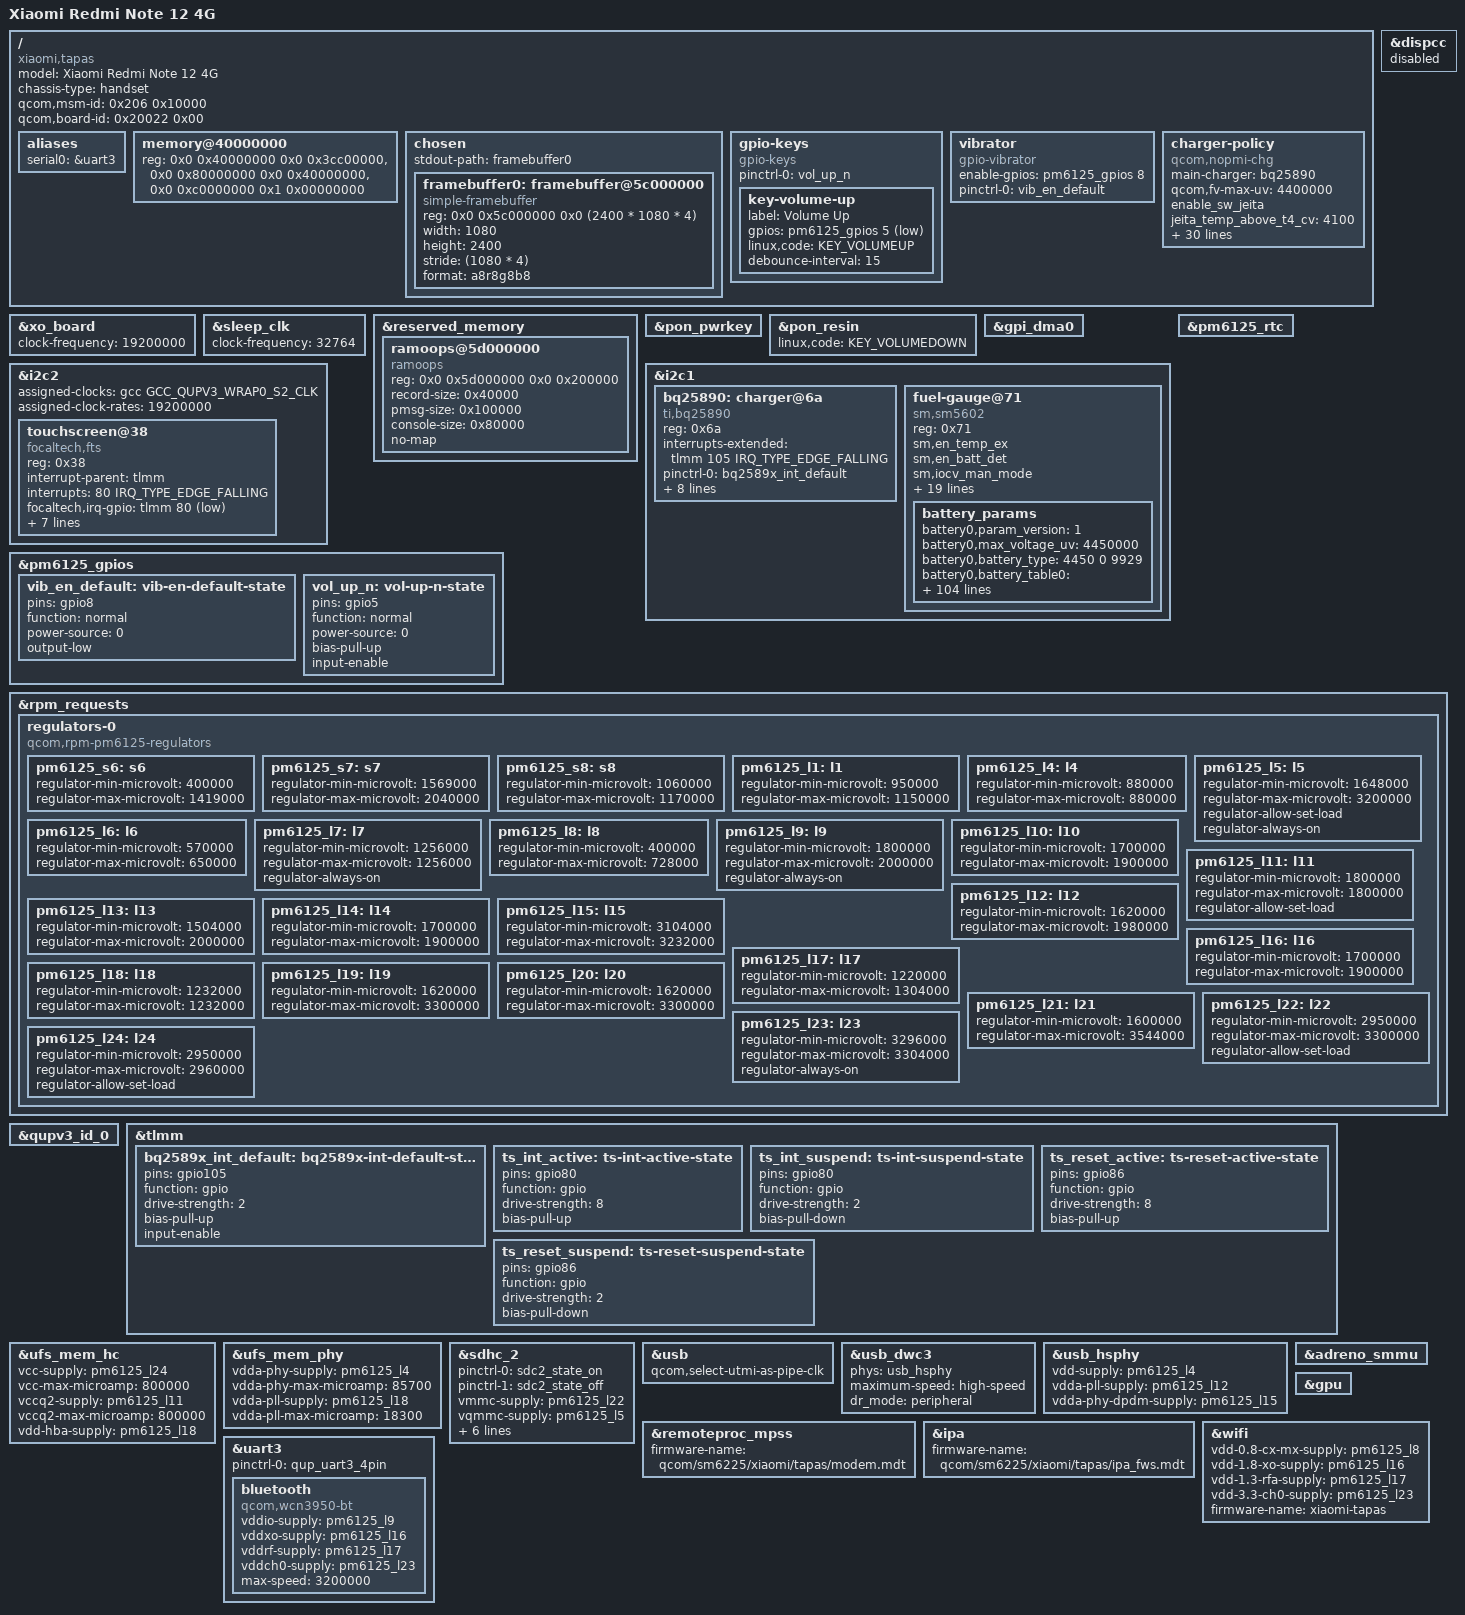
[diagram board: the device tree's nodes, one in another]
// SPDX-License-Identifier: GPL-2.0-only
/*
 * Xiaomi Redmi Note 12 4G (tapas), SM6225 "Khaje".
 *
 * Built on the sm6225.dtsi of the sm6225-mainline kernel
 * (https://gitlab.postmarketos.org/sm6225-mainline), laid out like its
 * Redmi Note 11 (spes) board file, which shares most of the tapas board:
 * same PMIC, charger, Type-C controller and I2C buses.
 *
 * Display is the framebuffer the bootloader leaves on (no panel driver).
 * The bootloader does not see this DTB (shim/start.S passes it), so it does
 * not fill in the memory node either: the layout below is the one ABL
 * reports on the 6 GB model.
 */
/dts-v1/;
#include "sm6225.dtsi"
#include "pm6125.dtsi"
#include <dt-bindings/gpio/gpio.h>
#include <dt-bindings/interrupt-controller/irq.h>
#include <dt-bindings/input/linux-event-codes.h>

/delete-node/ &{/memory@80000000};

/ {
	model = "Xiaomi Redmi Note 12 4G";
	compatible = "xiaomi,tapas", "qcom,sm6225";
	chassis-type = "handset";

	qcom,msm-id = <0x206 0x10000>;
	qcom,board-id = <0x20022 0x00>;

	aliases {
		serial0 = &uart3;
	};

	/* ABL's "RAM Partitions" on the 6 GB tapas */
	memory@40000000 {
		device_type = "memory";
		reg = <0x0 0x40000000 0x0 0x3cc00000>,
		      <0x0 0x80000000 0x0 0x40000000>,
		      <0x0 0xc0000000 0x1 0x00000000>;
	};

	chosen {
		#address-cells = <2>;
		#size-cells = <2>;
		ranges;
		stdout-path = "framebuffer0";

		/* 1080x2400, 32 bpp: the splash buffer the bootloader scans out */
		framebuffer0: framebuffer@5c000000 {
			compatible = "simple-framebuffer";
			reg = <0x0 0x5c000000 0x0 (2400 * 1080 * 4)>;
			width = <1080>;
			height = <2400>;
			stride = <(1080 * 4)>;
			format = "a8r8g8b8";
		};
	};

	gpio-keys {
		compatible = "gpio-keys";
		pinctrl-names = "default";
		pinctrl-0 = <&vol_up_n>;

		key-volume-up {
			label = "Volume Up";
			gpios = <&pm6125_gpios 5 GPIO_ACTIVE_LOW>;
			linux,code = <KEY_VOLUMEUP>;
			debounce-interval = <15>;
		};
	};

	/* Stock vibrator_gpio: the motor runs while PM6125 GPIO8 is high */
	vibrator {
		compatible = "gpio-vibrator";
		enable-gpios = <&pm6125_gpios 8 GPIO_ACTIVE_HIGH>;
		pinctrl-0 = <&vib_en_default>;
		pinctrl-names = "default";
	};

	/*
	 * Xiaomi "No-PMI" charger policy, as on spes: turns the SM5602 fuel
	 * gauge ("bms") and the bq2589x buck into the "battery" and "usb"
	 * supplies that UPower reads. Values from the stock qcom,nopmi-chg
	 * node. No pd-source: the rt1711h Type-C port is left out for now.
	 */
	charger-policy {
		compatible = "qcom,nopmi-chg";
		main-charger = <&bq25890>;
		qcom,fv-max-uv = <4400000>;

		enable_sw_jeita;
		jeita_temp_above_t4_cv = <4100>;
		jeita_temp_t3_to_t4_cv = <4100>;
		jeita_temp_t2_to_t3_cv = <4450>;
		jeita_temp_t1p5_to_t2_cv = <4450>;
		jeita_temp_t1_to_t1p5_cv = <4450>;
		jeita_temp_t0_to_t1_cv = <4450>;
		jeita_temp_tn1_to_t0_cv = <4450>;
		jeita_temp_below_t0_cv = <4450>;
		temp_t4_thres = <60>;
		temp_t4_thres_minus_x_degree = <58>;
		temp_t3_thres = <48>;
		temp_t3_thres_minus_x_degree = <46>;
		temp_t2_thres = <15>;
		temp_t2_thres_plus_x_degree = <17>;
		temp_t1p5_thres = <10>;
		temp_t1p5_thres_plus_x_degree = <11>;
		temp_t1_thres = <5>;
		temp_t1_thres_plus_x_degree = <6>;
		temp_t0_thres = <0>;
		temp_t0_thres_plus_x_degree = <1>;
		temp_tn1_thres = <(-10)>;
		temp_tn1_thres_plus_x_degree = <(-9)>;
		temp_neg_10_thres = <(-10)>;
		temp_t3_to_t4_fcc = <2350>;
		temp_t2_to_t3_fcc = <5950>;
		temp_t1p5_to_t2_fcc = <3900>;
		temp_t1_to_t1p5_fcc = <2400>;
		temp_t0_to_t1_fcc = <950>;
		temp_tn1_to_t0_fcc = <490>;
		nopmi,thermal-mitigation = <5950000 5400000 5000000 4500000 4000000
					    3700000 3500000 3000000 2800000 2500000
					    2000000 1500000 1000000 800000 500000
					    350000 800000 800000>;
	};
};

/*
 * The SoC dtsi leaves the board clock rates to the board. Without them
 * xo_board never registers, bi_tcxo stays an orphan at 0 Hz, and the QUP
 * DFS tables read back as all zeros (geni_i2c: "Unsupported SE source
 * clock"), so i2c2 and the touchscreen never probe.
 */
&xo_board {
	clock-frequency = <19200000>;
};

&sleep_clk {
	clock-frequency = <32764>;
};

&reserved_memory {
	/*
	 * Same place and layout as the stock kernel, so the log of a boot
	 * that died can be read from Android or recovery afterwards.
	 */
	ramoops@5d000000 {
		compatible = "ramoops";
		reg = <0x0 0x5d000000 0x0 0x200000>;
		record-size = <0x40000>;
		pmsg-size = <0x100000>;
		console-size = <0x80000>;
		no-map;
	};
};

/*
 * Leave the display clocks as the bootloader set them: dispcc reprograms
 * its PLL when it probes, which broke the splash scanout under the
 * framebuffer (grey screen, blue stripes). The MDSS is disabled anyway.
 */
&dispcc {
	status = "disabled";
};

&pon_pwrkey {
	status = "okay";
};

&pon_resin {
	linux,code = <KEY_VOLUMEDOWN>;
	status = "okay";
};

&gpi_dma0 {
	status = "okay";
};

/*
 * Charger and fuel gauge, at the stock addresses. Left out for now: the
 * rt1711h Type-C port (0x4e, it would renegotiate the USB link the
 * bring-up shell runs on), the sc8551/ln8000 divider pumps and the audio
 * amplifiers.
 */
&i2c1 {
	status = "okay";

	/* Stock "ti,bq2589x-1"; the sm6225-mainline driver knows its id */
	bq25890: charger@6a {
		compatible = "ti,bq25890";
		reg = <0x6a>;
		interrupts-extended = <&tlmm 105 IRQ_TYPE_EDGE_FALLING>;
		pinctrl-0 = <&bq2589x_int_default>;
		pinctrl-names = "default";

		/* Stock charge-voltage, charge-current and term-current */
		ti,battery-regulation-voltage = <4450000>;
		ti,charge-current = <2000000>;
		ti,termination-current = <256000>;
		ti,precharge-current = <128000>;
		ti,minimum-sys-voltage = <3500000>;
		ti,boost-voltage = <5000000>;
		ti,boost-max-current = <1500000>;
		/*
		 * No ti,enable-auto-dpdm: stock routes D+/D- to the charger
		 * through a switch (gpio66) for that, and here they belong to
		 * the USB gadget.
		 */
		/*
		 * Keep the bootloader's register state: a chip reset turns
		 * OTG_CONFIG back on (its default), and the phone would start
		 * putting 5 V on the cable to the fastboot host.
		 */
		linux,skip-reset;
	};

	fuel-gauge@71 {
		compatible = "sm,sm5602";
		reg = <0x71>;

		/* From the stock node; profile 0 is used without batt_verify */
		sm,en_temp_ex;
		sm,en_batt_det;
		sm,iocv_man_mode;
		sm,misc = <2048>;
		sm,aging_ctrl = <289>;
		sm,cycle_cfg = <28672>;
		sm,rsns = <0>;
		sm,rtrace = <2000>;
		sm,fg_irq_set = <2047>;
		sm,low_soc1 = <1>;
		sm,low_soc2 = <15>;
		sm,v_l_alarm = <3400>;
		sm,v_h_alarm = <4450>;
		sm,battery_table_num = <0>;
		sm,param_version = <6>;
		sm,t_l_alarm_in = <54>;
		sm,t_h_alarm_in = <1>;
		sm,t_l_alarm_ex = <54232>;
		sm,t_h_alarm_ex = <37445>;
		sm,shutdown-delay-enable;
		sm,soc_decimal_rate = <0 38 10 35 20 33 30 33 40 33 50 33 60 33 70 30 80 25 90 20 95 10>;

		battery_params {
			/* battery 0 */
			battery0,param_version = <1>;
			battery0,max_voltage_uv = <4450000>;
			battery0,battery_type = <4450 0 9929>;
			battery0,battery_table0 = <5120 6973 7262 7482 7552 7565 7571 7594 7674 7742 7799 7858 7945 8039 8115 8166 8262 8427 8609 8736 8826 8985 9056 9420>;
			battery0,battery_table1 = <0 104 498 1024 1418 1944 2732 3258 4967 6938 8909 10880 12852 14166 14823 15480 16794 18766 20737 22051 22971 24811 25600 25830>;
			battery0,battery_table2 = <5148 4113 3599 3085 2827 2571 2570 2313>;
			battery0,alpha = <204>;
			battery0,beta = <37>;
			battery0,rs = <95>;
			battery0,rs_value = <80 266 14336 72>;
			battery0,vit_period = <12634>;
			battery0,volt_cal = <32768>;
			battery0,mix_value = <3>;
			battery0,curr_offset = <0>;
			battery0,curr_slope = <32896>;
			battery0,topoff_soc = <7 300 100>;
			battery0,temp_std = <25>;
			battery0,temp_offset = <0 11 1 0 8 (-1)>;
			battery0,temp_cal = <0 6 1 11 (-1) 0 6 1 9 1>;
			battery0,ext_temp_cal = <0 2 1 2 1 1 2 3 2 3>;
			battery0,tem_poff = <3400 100>;
			battery0,fcm_offset = <82>;
			battery0,thermal_table = <20590 20277 19975 19648 19318 18981 18621 18269 17909 17527 17156 16757 16350 15946 15522 15094 14661 14218 13771 13308 12843 12377 11906 11424 10950 10438 9952 9450 8936 8431 7911 7406 6888 6352 5846 5326 4851 4324 3798 3268 2748 2236 1704 1197 673 158 63081 62577 62072 61569 61051 60556 60065 59582 59105 58629 58162 57698 57243 56793 56351 55911 55476 55051 54629 54215 53810 53409 53016 52628 52248 51877 51510 51155 50800 50457 50118 49786 49462 49143 48833 48530 48238 47949 47670 47394 47126 46866 46609 46359 46114 45876 45641 45412 45189 44973 44760 44554 44350 44152 43959>;

			/* battery 1 */
			battery1,param_version = <2>;
			battery1,max_voltage_uv = <4450000>;
			battery1,battery_type = <4450 0 9984>;
			battery1,battery_table0 = <5120 6965 7206 7404 7526 7564 7575 7606 7680 7752 7805 7869 7954 8048 8125 8173 8272 8435 8615 8740 8827 8983 9051 9420>;
			battery1,battery_table1 = <0 102 403 795 1187 1840 2884 3406 5103 7062 9020 10978 12936 14242 14894 15547 16853 18811 20769 22075 22988 24816 25600 25830>;
			battery1,battery_table2 = <5920 4628 4113 3342 3084 2827 2570 2570>;
			battery1,alpha = <204>;
			battery1,beta = <37>;
			battery1,rs = <95>;
			battery1,rs_value = <80 266 14336 72>;
			battery1,vit_period = <12634>;
			battery1,volt_cal = <32768>;
			battery1,mix_value = <3>;
			battery1,curr_offset = <0>;
			battery1,curr_slope = <32896>;
			battery1,topoff_soc = <7 300 100>;
			battery1,temp_std = <25>;
			battery1,temp_offset = <0 11 1 0 8 (-1)>;
			battery1,temp_cal = <0 6 1 11 (-1) 0 6 1 9 1>;
			battery1,ext_temp_cal = <0 2 1 2 1 1 2 3 2 3>;
			battery1,tem_poff = <3400 100>;
			battery1,fcm_offset = <103>;
			battery1,thermal_table = <20590 20277 19975 19648 19318 18981 18621 18269 17909 17527 17156 16757 16350 15946 15522 15094 14661 14218 13771 13308 12843 12377 11906 11424 10950 10438 9952 9450 8936 8431 7911 7406 6888 6352 5846 5326 4851 4324 3798 3268 2748 2236 1704 1197 673 158 63081 62577 62072 61569 61051 60556 60065 59582 59105 58629 58162 57698 57243 56793 56351 55911 55476 55051 54629 54215 53810 53409 53016 52628 52248 51877 51510 51155 50800 50457 50118 49786 49462 49143 48833 48530 48238 47949 47670 47394 47126 46866 46609 46359 46114 45876 45641 45412 45189 44973 44760 44554 44350 44152 43959>;

			/* battery 2 */
			battery2,param_version = <1>;
			battery2,max_voltage_uv = <4450000>;
			battery2,battery_type = <4450 0 9929>;
			battery2,battery_table0 = <5120 6973 7262 7482 7552 7565 7571 7594 7674 7742 7799 7858 7945 8039 8115 8166 8262 8427 8609 8736 8826 8985 9056 9420>;
			battery2,battery_table1 = <0 104 498 1024 1418 1944 2732 3258 4967 6938 8909 10880 12852 14166 14823 15480 16794 18766 20737 22051 22971 24811 25600 25830>;
			battery2,battery_table2 = <5148 4113 3599 3085 2827 2571 2570 2313>;
			battery2,alpha = <204>;
			battery2,beta = <37>;
			battery2,rs = <95>;
			battery2,rs_value = <80 266 14336 72>;
			battery2,vit_period = <12634>;
			battery2,volt_cal = <32768>;
			battery2,mix_value = <3>;
			battery2,curr_offset = <0>;
			battery2,curr_slope = <32896>;
			battery2,topoff_soc = <7 300 100>;
			battery2,temp_std = <25>;
			battery2,temp_offset = <0 11 1 0 8 (-1)>;
			battery2,temp_cal = <0 6 1 11 (-1) 0 6 1 9 1>;
			battery2,ext_temp_cal = <0 2 1 2 1 1 2 3 2 3>;
			battery2,tem_poff = <3400 100>;
			battery2,fcm_offset = <82>;
			battery2,thermal_table = <20590 20277 19975 19648 19318 18981 18621 18269 17909 17527 17156 16757 16350 15946 15522 15094 14661 14218 13771 13308 12843 12377 11906 11424 10950 10438 9952 9450 8936 8431 7911 7406 6888 6352 5846 5326 4851 4324 3798 3268 2748 2236 1704 1197 673 158 63081 62577 62072 61569 61051 60556 60065 59582 59105 58629 58162 57698 57243 56793 56351 55911 55476 55051 54629 54215 53810 53409 53016 52628 52248 51877 51510 51155 50800 50457 50118 49786 49462 49143 48833 48530 48238 47949 47670 47394 47126 46866 46609 46359 46114 45876 45641 45412 45189 44973 44760 44554 44350 44152 43959>;

			/* battery 3 */
			battery3,param_version = <1>;
			battery3,max_voltage_uv = <4450000>;
			battery3,battery_type = <4450 0 9932>;
			battery3,battery_table0 = <5120 6962 7165 7385 7542 7564 7574 7605 7678 7747 7797 7858 7942 8044 8116 8162 8257 8421 8604 8731 8820 8981 9057 9420>;
			battery3,battery_table1 = <0 102 329 721 1245 1769 2817 3340 5042 7007 8971 10935 12899 14208 14863 15517 16827 18791 20755 22064 22981 24814 25600 25830>;
			battery3,battery_table2 = <4891 3857 3598 3084 2827 2570 2314 2313>;
			battery3,alpha = <204>;
			battery3,beta = <37>;
			battery3,rs = <95>;
			battery3,rs_value = <80 266 14336 72>;
			battery3,vit_period = <12634>;
			battery3,volt_cal = <32768>;
			battery3,mix_value = <3>;
			battery3,curr_offset = <0>;
			battery3,curr_slope = <32896>;
			battery3,topoff_soc = <7 300 100>;
			battery3,temp_std = <25>;
			battery3,temp_offset = <0 11 1 0 8 (-1)>;
			battery3,temp_cal = <0 6 1 11 (-1) 0 6 1 9 1>;
			battery3,ext_temp_cal = <0 2 1 2 1 1 2 3 2 3>;
			battery3,tem_poff = <3400 100>;
			battery3,fcm_offset = <103>;
			battery3,thermal_table = <20590 20277 19975 19648 19318 18981 18621 18269 17909 17527 17156 16757 16350 15946 15522 15094 14661 14218 13771 13308 12843 12377 11906 11424 10950 10438 9952 9450 8936 8431 7911 7406 6888 6352 5846 5326 4851 4324 3798 3268 2748 2236 1704 1197 673 158 63081 62577 62072 61569 61051 60556 60065 59582 59105 58629 58162 57698 57243 56793 56351 55911 55476 55051 54629 54215 53810 53409 53016 52628 52248 51877 51510 51155 50800 50457 50118 49786 49462 49143 48833 48530 48238 47949 47670 47394 47126 46866 46609 46359 46114 45876 45641 45412 45189 44973 44760 44554 44350 44152 43959>;
		};
	};
};

/* Touchscreen: FocalTech FT5452 (chip id 0x5452), pins as in stock */
&i2c2 {
	/*
	 * geni_i2c rejects the SE core clock unless it is exactly 19.2 or
	 * 32 MHz ("Unsupported SE source clock", -EINVAL): GCC_QUPV3_WRAP0_S2_CLK
	 * has no default rate here, so the i2c2 bus never probes and the
	 * touchscreen is dead. Pin the RCG to XO 19.2 MHz.
	 */
	assigned-clocks = <&gcc GCC_QUPV3_WRAP0_S2_CLK>;
	assigned-clock-rates = <19200000>;
	status = "okay";

	touchscreen@38 {
		compatible = "focaltech,fts";
		reg = <0x38>;
		interrupt-parent = <&tlmm>;
		interrupts = <80 IRQ_TYPE_EDGE_FALLING>;
		/* the driver picks a falling edge only when this gpio is active-low */
		focaltech,irq-gpio = <&tlmm 80 GPIO_ACTIVE_LOW>;
		focaltech,reset-gpio = <&tlmm 86 GPIO_ACTIVE_LOW>;
		focaltech,avdd-gpio = <&tlmm 36 GPIO_ACTIVE_HIGH>;
		/*
		 * The firmware reports 10x the panel resolution, but the driver
		 * reads only the top 12 bits of it: 1/8 of 10799x23999.
		 */
		focaltech,display-coords = <0 0 1349 2999>;
		focaltech,max-touch-number = <10>;
		pinctrl-names = "pmx_ts_active", "pmx_ts_suspend";
		pinctrl-0 = <&ts_int_active &ts_reset_active>;
		pinctrl-1 = <&ts_int_suspend &ts_reset_suspend>;
		vcc_i2c-supply = <&pm6125_l9>;
	};
};

&pm6125_gpios {
	vib_en_default: vib-en-default-state {
		pins = "gpio8";
		function = "normal";
		power-source = <0>;
		output-low;
	};

	vol_up_n: vol-up-n-state {
		pins = "gpio5";
		function = "normal";
		power-source = <0>;
		bias-pull-up;
		input-enable;
	};
};

&pm6125_rtc {
	status = "okay";
};

/* Ranges from the stock tapas device tree */
&rpm_requests {
	regulators-0 {
		compatible = "qcom,rpm-pm6125-regulators";

		pm6125_s6: s6 {
			regulator-min-microvolt = <400000>;
			regulator-max-microvolt = <1419000>;
		};

		pm6125_s7: s7 {
			regulator-min-microvolt = <1569000>;
			regulator-max-microvolt = <2040000>;
		};

		pm6125_s8: s8 {
			regulator-min-microvolt = <1060000>;
			regulator-max-microvolt = <1170000>;
		};

		pm6125_l1: l1 {
			regulator-min-microvolt = <950000>;
			regulator-max-microvolt = <1150000>;
		};

		/* UFS and USB PHYs */
		pm6125_l4: l4 {
			regulator-min-microvolt = <880000>;
			regulator-max-microvolt = <880000>;
		};

		/* SD card I/O; SDHCI breaks if it is ever turned off (spes) */
		pm6125_l5: l5 {
			regulator-min-microvolt = <1648000>;
			regulator-max-microvolt = <3200000>;
			regulator-allow-set-load;
			regulator-always-on;
		};

		pm6125_l6: l6 {
			regulator-min-microvolt = <570000>;
			regulator-max-microvolt = <650000>;
		};

		/* SD card I/O bias (stock vdd-io-bias-supply), 1.256V */
		pm6125_l7: l7 {
			regulator-min-microvolt = <1256000>;
			regulator-max-microvolt = <1256000>;
			regulator-always-on;
		};

		pm6125_l8: l8 {
			regulator-min-microvolt = <400000>;
			regulator-max-microvolt = <728000>;
		};

		pm6125_l9: l9 {
			regulator-min-microvolt = <1800000>;
			regulator-max-microvolt = <2000000>;
			regulator-always-on;
		};

		pm6125_l10: l10 {
			regulator-min-microvolt = <1700000>;
			regulator-max-microvolt = <1900000>;
		};

		/* UFS VCCQ2 */
		pm6125_l11: l11 {
			regulator-min-microvolt = <1800000>;
			regulator-max-microvolt = <1800000>;
			regulator-allow-set-load;
		};

		/* USB PHY PLL */
		pm6125_l12: l12 {
			regulator-min-microvolt = <1620000>;
			regulator-max-microvolt = <1980000>;
		};

		pm6125_l13: l13 {
			regulator-min-microvolt = <1504000>;
			regulator-max-microvolt = <2000000>;
		};

		pm6125_l14: l14 {
			regulator-min-microvolt = <1700000>;
			regulator-max-microvolt = <1900000>;
		};

		/* USB PHY D+/D- */
		pm6125_l15: l15 {
			regulator-min-microvolt = <3104000>;
			regulator-max-microvolt = <3232000>;
		};

		pm6125_l16: l16 {
			regulator-min-microvolt = <1700000>;
			regulator-max-microvolt = <1900000>;
		};

		pm6125_l17: l17 {
			regulator-min-microvolt = <1220000>;
			regulator-max-microvolt = <1304000>;
		};

		/* UFS PHY PLL and reference clock */
		pm6125_l18: l18 {
			regulator-min-microvolt = <1232000>;
			regulator-max-microvolt = <1232000>;
		};

		pm6125_l19: l19 {
			regulator-min-microvolt = <1620000>;
			regulator-max-microvolt = <3300000>;
		};

		pm6125_l20: l20 {
			regulator-min-microvolt = <1620000>;
			regulator-max-microvolt = <3300000>;
		};

		pm6125_l21: l21 {
			regulator-min-microvolt = <1600000>;
			regulator-max-microvolt = <3544000>;
		};

		/* SD card */
		pm6125_l22: l22 {
			regulator-min-microvolt = <2950000>;
			regulator-max-microvolt = <3300000>;
			regulator-allow-set-load;
		};

		pm6125_l23: l23 {
			regulator-min-microvolt = <3296000>;
			regulator-max-microvolt = <3304000>;
			regulator-always-on;
		};

		/* UFS VCC */
		pm6125_l24: l24 {
			regulator-min-microvolt = <2950000>;
			regulator-max-microvolt = <2960000>;
			regulator-allow-set-load;
		};
	};
};

&qupv3_id_0 {
	status = "okay";
};

&tlmm {
	bq2589x_int_default: bq2589x-int-default-state {
		pins = "gpio105";
		function = "gpio";
		drive-strength = <2>;
		bias-pull-up;
		input-enable;
	};

	ts_int_active: ts-int-active-state {
		pins = "gpio80";
		function = "gpio";
		drive-strength = <8>;
		bias-pull-up;
	};

	ts_int_suspend: ts-int-suspend-state {
		pins = "gpio80";
		function = "gpio";
		drive-strength = <2>;
		bias-pull-down;
	};

	ts_reset_active: ts-reset-active-state {
		pins = "gpio86";
		function = "gpio";
		drive-strength = <8>;
		bias-pull-up;
	};

	ts_reset_suspend: ts-reset-suspend-state {
		pins = "gpio86";
		function = "gpio";
		drive-strength = <2>;
		bias-pull-down;
	};
};

&ufs_mem_hc {
	vcc-supply = <&pm6125_l24>;
	vcc-max-microamp = <800000>;
	vccq2-supply = <&pm6125_l11>;
	vccq2-max-microamp = <800000>;
	vdd-hba-supply = <&pm6125_l18>;
	status = "okay";
};

&ufs_mem_phy {
	vdda-phy-supply = <&pm6125_l4>;
	vdda-phy-max-microamp = <85700>;
	vdda-pll-supply = <&pm6125_l18>;
	vdda-pll-max-microamp = <18300>;
	status = "okay";
};

/* Card detect (gpio88) is left out: a card must be inserted at boot */
&sdhc_2 {
	pinctrl-names = "default", "sleep";
	pinctrl-0 = <&sdc2_state_on>;
	pinctrl-1 = <&sdc2_state_off>;

	vmmc-supply = <&pm6125_l22>;
	vqmmc-supply = <&pm6125_l5>;

	/* sm6225.dtsi leaves bus-width out, and UHS-I needs 4 bits */
	bus-width = <4>;
	no-sdio;
	no-mmc;
	/* Stock qcom,dll-hsr-list */
	qcom,ddr-config = <0x80040868>;
	/*
	 * SDR104 tuning always fails (-5) on mainline, while Android runs the
	 * same card at SDR104. Stay at 3.3 V high speed, which needs no tuning.
	 */
	no-1-8-v;

	broken-cd;
	status = "okay";
};

&usb {
	qcom,select-utmi-as-pipe-clk;
	status = "okay";
};

/* Peripheral only for now: the bring-up shell is a USB gadget */
&usb_dwc3 {
	phys = <&usb_hsphy>;
	phy-names = "usb2-phy";
	maximum-speed = "high-speed";
	dr_mode = "peripheral";
};

&usb_hsphy {
	vdd-supply = <&pm6125_l4>;
	vdda-pll-supply = <&pm6125_l12>;
	vdda-phy-dpdm-supply = <&pm6125_l15>;
	status = "okay";
};

/*
 * GPU: Adreno 610 (a610, chipid 0x06010001). No real GMU -> the mainline
 * "gmu-wrapper"; gpucc (qcom,sm6225-gpucc) and gmu_wrapper are already okay
 * in sm6225.dtsi, only the gpu and its SMMU are disabled. drm/msm (DRM_MSM=y)
 * and CONFIG_SM_GPUCC_6225=y are in the base config. The zap region
 * pil_gpu_mem (0x56615000, no-map) is reserved in sm6225.dtsi.
 *
 * Firmware (put in the rootfs /lib/firmware/qcom/, pulled from the stock
 * /vendor/firmware): a630_sqe.fw and the split zap a610_zap.mdt + .b00..b02.
 */
&adreno_smmu {
	status = "okay";
};

&gpu {
	status = "okay";
};

/*
 * Modem (SIM, and the WCN3950 Wi-Fi firmware runs on it too). The stock
 * modem.mdt is relocatable and spans exactly pil_modem_mem (0x4ab00000,
 * 0x6900000). Userspace: rmtfs (EFS from modemst1/2), tqftpserv (serves
 * wlanmdsp.mbn from this directory); pd-mapper is in the kernel.
 */
&remoteproc_mpss {
	firmware-name = "qcom/sm6225/xiaomi/tapas/modem.mdt";
	status = "okay";
};

/* Mobile data; stock ipa_fws (/vendor/firmware) is relocatable */
&ipa {
	firmware-name = "qcom/sm6225/xiaomi/tapas/ipa_fws.mdt";
	status = "okay";
};

/*
 * WCN3950 (stock ro.hardware.wlan.chip) Wi-Fi/BT, supplies as in the stock
 * icnss and bt_wcn3990 nodes. firmware-name makes ath10k look in
 * ath10k/WCN3990/hw1.0/xiaomi-tapas/ first, where board.bin is the stock
 * bdwlan for the global variant.
 */
&wifi {
	vdd-0.8-cx-mx-supply = <&pm6125_l8>;
	vdd-1.8-xo-supply = <&pm6125_l16>;
	vdd-1.3-rfa-supply = <&pm6125_l17>;
	vdd-3.3-ch0-supply = <&pm6125_l23>;
	firmware-name = "xiaomi-tapas";
	status = "okay";
};

/* Stock qupv3_se3_4uart (msm-geni-serial-hs) */
&uart3 {
	pinctrl-0 = <&qup_uart3_4pin>;
	status = "okay";

	bluetooth {
		compatible = "qcom,wcn3950-bt";
		vddio-supply = <&pm6125_l9>;
		vddxo-supply = <&pm6125_l16>;
		vddrf-supply = <&pm6125_l17>;
		vddch0-supply = <&pm6125_l23>;
		max-speed = <3200000>;
	};
};
